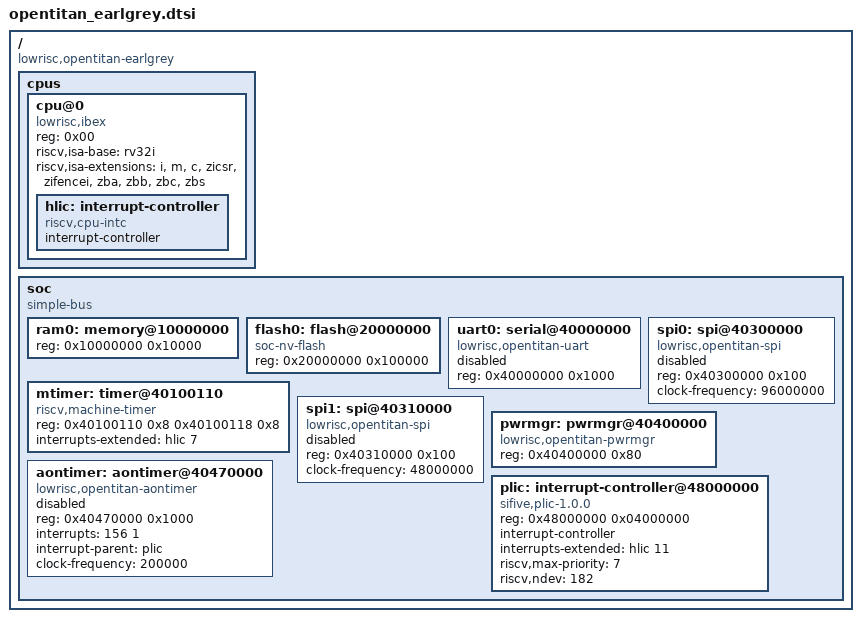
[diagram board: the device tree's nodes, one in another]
/*
 * Copyright (c) 2023 by Rivos Inc.
 *
 * SPDX-License-Identifier: Apache-2.0
 */

/ {
	compatible = "lowrisc,opentitan-earlgrey";
	#address-cells = <0x01>;
	#size-cells = <0x01>;

	cpus {
		#address-cells = <0x01>;
		#size-cells = <0x00>;

		cpu@0 {
			compatible = "lowrisc,ibex", "riscv";
			reg = <0x00>;
			device_type = "cpu";
			riscv,isa-base = "rv32i";
			riscv,isa-extensions = "i", "m", "c", "zicsr", "zifencei",
					       "zba", "zbb", "zbc", "zbs";
			status = "okay";

			hlic: interrupt-controller {
				compatible = "riscv,cpu-intc";
				#interrupt-cells = <0x01>;
				interrupt-controller;
			};
		};
	};

	soc {
		compatible = "simple-bus";
		ranges;
		#address-cells = <0x01>;
		#size-cells = <0x01>;

		ram0: memory@10000000 {
			reg = <0x10000000 0x10000>;
			device_type = "memory";
		};

		flash0: flash@20000000 {
			compatible = "soc-nv-flash";
			reg = <0x20000000 0x100000>;
		};

		uart0: serial@40000000 {
			compatible = "lowrisc,opentitan-uart";
			reg = <0x40000000 0x1000>;
			status = "disabled";
		};

		mtimer: timer@40100110 {
			compatible = "riscv,machine-timer";
			reg = <0x40100110 0x8 0x40100118 0x8>;
			reg-names = "mtime", "mtimecmp";
			interrupts-extended = <&hlic 7>;
		};

		spi0: spi@40300000 {
			compatible = "lowrisc,opentitan-spi";
			reg = <0x40300000 0x100>;
			clock-frequency = <96000000>;
			#address-cells = <1>;
			#size-cells = <0>;
			status = "disabled";
		};

		spi1: spi@40310000 {
			compatible = "lowrisc,opentitan-spi";
			reg = <0x40310000 0x100>;
			clock-frequency = <48000000>;
			#address-cells = <1>;
			#size-cells = <0>;
			status = "disabled";
		};

		pwrmgr: pwrmgr@40400000 {
			compatible = "lowrisc,opentitan-pwrmgr";
			reg = <0x40400000 0x80>;
			status = "okay";
		};

		aontimer: aontimer@40470000 {
			compatible = "lowrisc,opentitan-aontimer";
			reg = <0x40470000 0x1000>;
			interrupts = <156 1>;
			interrupt-names = "wdog_bark";
			interrupt-parent = <&plic>;
			clock-frequency = <200000>;
			status = "disabled";
		};

		plic: interrupt-controller@48000000 {
			compatible = "sifive,plic-1.0.0";
			reg = <0x48000000 0x04000000>;
			#address-cells = <0>;
			#interrupt-cells = <2>;
			interrupt-controller;
			interrupts-extended = <&hlic 11>;
			riscv,max-priority = <7>;
			riscv,ndev = <182>;
			status = "okay";
		};
	};
};
